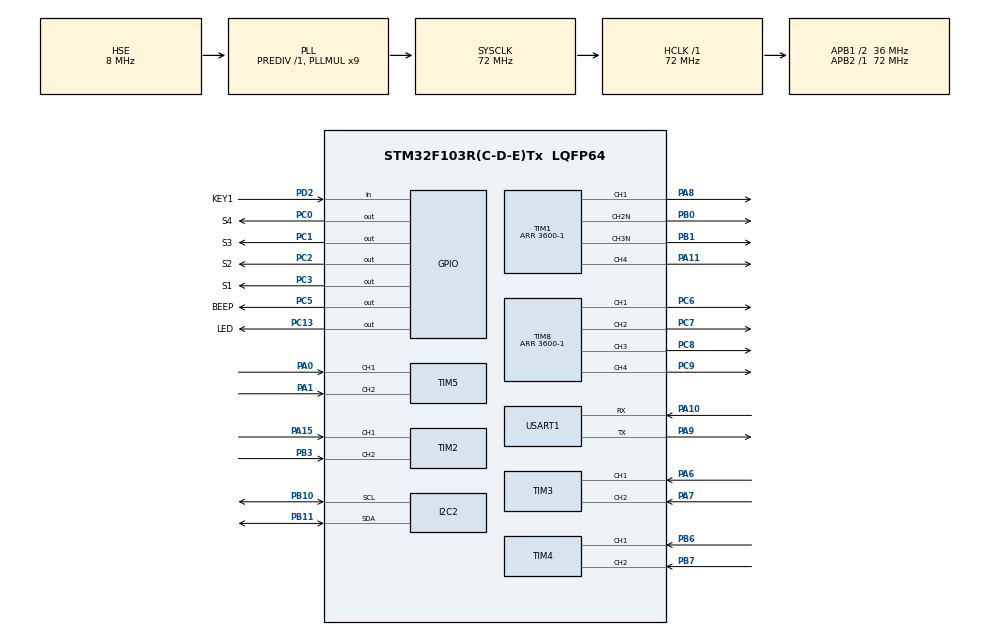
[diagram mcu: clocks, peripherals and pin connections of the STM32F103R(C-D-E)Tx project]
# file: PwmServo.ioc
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Dma.Request0=USART1_TX
Dma.Request1=USART1_RX
Dma.USART1_RX.1.Direction=DMA_PERIPH_TO_MEMORY
Dma.USART1_RX.1.Instance=DMA1_Channel5
Dma.USART1_RX.1.MemDataAlignment=DMA_MDATAALIGN_BYTE
Dma.USART1_RX.1.MemInc=DMA_MINC_ENABLE
Dma.USART1_RX.1.Mode=DMA_NORMAL
Dma.USART1_RX.1.PeriphDataAlignment=DMA_PDATAALIGN_BYTE
Dma.USART1_RX.1.PeriphInc=DMA_PINC_DISABLE
Dma.USART1_RX.1.Priority=DMA_PRIORITY_LOW
Dma.USART1_TX.0.Direction=DMA_MEMORY_TO_PERIPH
Dma.USART1_TX.0.Instance=DMA1_Channel4
Dma.USART1_TX.0.MemDataAlignment=DMA_MDATAALIGN_BYTE
Dma.USART1_TX.0.MemInc=DMA_MINC_ENABLE
Dma.USART1_TX.0.Mode=DMA_NORMAL
Dma.USART1_TX.0.PeriphDataAlignment=DMA_PDATAALIGN_BYTE
Dma.USART1_TX.0.PeriphInc=DMA_PINC_DISABLE
Dma.USART1_TX.0.Priority=DMA_PRIORITY_LOW
I2C2.I2C_Mode=I2C_Fast
I2C2.OwnAddress=0x12
Mcu.Family=STM32F1
Mcu.Name=STM32F103R(C-D-E)Tx
Mcu.Package=LQFP64
NVIC.DMA1_Channel4_IRQn=true\:0\:0\:false\:false\:true\:false\:true\:true
NVIC.DMA1_Channel5_IRQn=true\:0\:0\:false\:false\:true\:false\:true\:true
NVIC.I2C2_ER_IRQn=true\:0\:0\:false\:false\:true\:true\:true\:true
NVIC.I2C2_EV_IRQn=true\:0\:0\:false\:false\:true\:true\:true\:true
NVIC.PriorityGroup=NVIC_PRIORITYGROUP_4
NVIC.TIM7_IRQn=true\:0\:0\:false\:false\:true\:true\:true\:true
NVIC.USART1_IRQn=true\:0\:0\:false\:false\:true\:true\:true\:true
PA0-WKUP.Signal=S_TIM5_CH1
PA1.Signal=S_TIM5_CH2
PA10.Mode=Asynchronous
PA10.Signal=USART1_RX
PA11.Signal=S_TIM1_CH4
PA13.Mode=Serial_Wire
PA13.Signal=SYS_JTMS-SWDIO
PA14.Mode=Serial_Wire
PA14.Signal=SYS_JTCK-SWCLK
PA15.Signal=S_TIM2_CH1_ETR
PA6.Signal=S_TIM3_CH1
PA7.Signal=S_TIM3_CH2
PA8.Signal=S_TIM1_CH1
PA9.Mode=Asynchronous
PA9.Signal=USART1_TX
PB0.Mode=PWM Generation2 CH2N
PB0.Signal=TIM1_CH2N
PB1.Mode=PWM Generation3 CH3N
PB1.Signal=TIM1_CH3N
PB10.Mode=I2C
PB10.Signal=I2C2_SCL
PB11.Mode=I2C
PB11.Signal=I2C2_SDA
PB3.Signal=S_TIM2_CH2
PB6.Signal=S_TIM4_CH1
PB7.Signal=S_TIM4_CH2
PC0.GPIO_Label=S4
PC0.GPIO_Speed=GPIO_SPEED_FREQ_HIGH
PC0.Signal=GPIO_Output
PC1.GPIO_Label=S3
PC1.GPIO_Speed=GPIO_SPEED_FREQ_HIGH
PC1.Signal=GPIO_Output
PC13-TAMPER-RTC.GPIO_Label=LED
PC13-TAMPER-RTC.Signal=GPIO_Output
PC2.GPIO_Label=S2
PC2.GPIO_Speed=GPIO_SPEED_FREQ_HIGH
PC2.Signal=GPIO_Output
PC3.GPIO_Label=S1
PC3.GPIO_Speed=GPIO_SPEED_FREQ_HIGH
PC3.Signal=GPIO_Output
PC5.GPIO_Label=BEEP
PC5.Signal=GPIO_Output
PC6.Signal=S_TIM8_CH1
PC7.Signal=S_TIM8_CH2
PC8.Signal=S_TIM8_CH3
PC9.Signal=S_TIM8_CH4
PD0-OSC_IN.Mode=HSE-External-Oscillator
PD0-OSC_IN.Signal=RCC_OSC_IN
PD1-OSC_OUT.Mode=HSE-External-Oscillator
PD1-OSC_OUT.Signal=RCC_OSC_OUT
PD2.GPIO_Label=KEY1
PD2.GPIO_PuPd=GPIO_PULLUP
PD2.Signal=GPIO_Input
ProjectManager.HeapSize=0x200
ProjectManager.StackSize=0x400
ProjectManager.TargetToolchain=STM32CubeIDE
RCC.AHBFreq_Value=72000000
RCC.APB1CLKDivider=RCC_HCLK_DIV2
RCC.APB1Freq_Value=36000000
RCC.APB1TimFreq_Value=72000000
RCC.APB2Freq_Value=72000000
RCC.APB2TimFreq_Value=72000000
RCC.HCLKFreq_Value=72000000
RCC.PLLMUL=RCC_PLL_MUL9
RCC.PLLSourceVirtual=RCC_PLLSOURCE_HSE
RCC.SYSCLKFreq_VALUE=72000000
RCC.SYSCLKSource=RCC_SYSCLKSOURCE_PLLCLK
RCC.USBFreq_Value=72000000
SH.S_TIM1_CH1.0=TIM1_CH1,PWM Generation1 CH1
SH.S_TIM1_CH4.0=TIM1_CH4,PWM Generation4 CH4
SH.S_TIM2_CH1_ETR.0=TIM2_CH1,Encoder_Interface
SH.S_TIM2_CH2.0=TIM2_CH2,Encoder_Interface
SH.S_TIM3_CH1.0=TIM3_CH1,Encoder_Interface
SH.S_TIM3_CH2.0=TIM3_CH2,Encoder_Interface
SH.S_TIM4_CH1.0=TIM4_CH1,Encoder_Interface
SH.S_TIM4_CH2.0=TIM4_CH2,Encoder_Interface
SH.S_TIM5_CH1.0=TIM5_CH1,Encoder_Interface
SH.S_TIM5_CH2.0=TIM5_CH2,Encoder_Interface
SH.S_TIM8_CH1.0=TIM8_CH1,PWM Generation1 CH1
SH.S_TIM8_CH2.0=TIM8_CH2,PWM Generation2 CH2
SH.S_TIM8_CH3.0=TIM8_CH3,PWM Generation3 CH3
SH.S_TIM8_CH4.0=TIM8_CH4,PWM Generation4 CH4
TIM1.AutoReloadPreload=TIM_AUTORELOAD_PRELOAD_ENABLE
TIM1.Channel-PWM\ Generation1\ CH1=TIM_CHANNEL_1
TIM1.Channel-PWM\ Generation2\ CH2N=TIM_CHANNEL_2
TIM1.Channel-PWM\ Generation3\ CH3N=TIM_CHANNEL_3
TIM1.Channel-PWM\ Generation4\ CH4=TIM_CHANNEL_4
TIM1.Period=3600-1
TIM2.EncoderMode=TIM_ENCODERMODE_TI12
TIM3.EncoderMode=TIM_ENCODERMODE_TI12
TIM4.EncoderMode=TIM_ENCODERMODE_TI12
TIM5.EncoderMode=TIM_ENCODERMODE_TI12
TIM7.AutoReloadPreload=TIM_AUTORELOAD_PRELOAD_ENABLE
TIM7.Period=9
TIM7.Prescaler=71
TIM7.TIM_MasterOutputTrigger=TIM_TRGO_RESET
TIM8.AutoReloadPreload=TIM_AUTORELOAD_PRELOAD_ENABLE
TIM8.Channel-PWM\ Generation1\ CH1=TIM_CHANNEL_1
TIM8.Channel-PWM\ Generation2\ CH2=TIM_CHANNEL_2
TIM8.Channel-PWM\ Generation3\ CH3=TIM_CHANNEL_3
TIM8.Channel-PWM\ Generation4\ CH4=TIM_CHANNEL_4
TIM8.Period=3600-1
USART1.VirtualMode=VM_ASYNC
VP_TIM1_VS_ClockSourceINT.Mode=Internal
VP_TIM7_VS_ClockSourceINT.Mode=Enable_Timer
VP_TIM8_VS_ClockSourceINT.Mode=Internal
board=custom

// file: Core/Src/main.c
/* USER CODE BEGIN Header */
/**
  ******************************************************************************
  * @file           : main.c
  * @brief          : Main program body
  ******************************************************************************
  * @attention
  *
  * <h2><center>&copy; Copyright (c) 2022 STMicroelectronics.
  * All rights reserved.</center></h2>
  *
  * This software component is licensed by ST under BSD 3-Clause license,
  * the "License"; You may not use this file except in compliance with the
  * License. You may obtain a copy of the License at:
  *                        opensource.org/licenses/BSD-3-Clause
  *
  ******************************************************************************
  */
/* USER CODE END Header */
#include "main.h"
#include "dma.h"
#include "i2c.h"
#include "tim.h"
#include "usart.h"
#include "gpio.h"

/* USER CODE BEGIN Includes */
#include "bsp.h"

/* USER CODE END Includes */

void SystemClock_Config(void);

int main(void)
{

  /* MCU Configuration--------------------------------------------------------*/

  /* Reset of all peripherals, Initializes the Flash interface and the Systick. */
  HAL_Init();

  /* Configure the system clock */
  SystemClock_Config();

  /* Initialize all configured peripherals */
  MX_GPIO_Init();
  MX_DMA_Init();
  MX_TIM7_Init();
  MX_I2C2_Init();
  MX_TIM1_Init();
  MX_TIM8_Init();
  MX_USART1_UART_Init();
  MX_TIM2_Init();
  MX_TIM3_Init();
  MX_TIM4_Init();
  MX_TIM5_Init();
  /* USER CODE BEGIN 2 */
  Bsp_Init();

  /* USER CODE END 2 */

  /* Infinite loop */
  /* USER CODE BEGIN WHILE */
  while (1)
  {
    Bsp_Loop();

    /* USER CODE END WHILE */

  }
}

void SystemClock_Config(void)
{
  RCC_OscInitTypeDef RCC_OscInitStruct = {0};
  RCC_ClkInitTypeDef RCC_ClkInitStruct = {0};

  /** Initializes the RCC Oscillators according to the specified parameters
  * in the RCC_OscInitTypeDef structure.
  */
  RCC_OscInitStruct.OscillatorType = RCC_OSCILLATORTYPE_HSE;
  RCC_OscInitStruct.HSEState = RCC_HSE_ON;
  RCC_OscInitStruct.HSEPredivValue = RCC_HSE_PREDIV_DIV1;
  RCC_OscInitStruct.HSIState = RCC_HSI_ON;
  RCC_OscInitStruct.PLL.PLLState = RCC_PLL_ON;
  RCC_OscInitStruct.PLL.PLLSource = RCC_PLLSOURCE_HSE;
  RCC_OscInitStruct.PLL.PLLMUL = RCC_PLL_MUL9;
  if (HAL_RCC_OscConfig(&RCC_OscInitStruct) != HAL_OK)
  {
    Error_Handler();
  }

  /** Initializes the CPU, AHB and APB buses clocks
  */
  RCC_ClkInitStruct.ClockType = RCC_CLOCKTYPE_HCLK|RCC_CLOCKTYPE_SYSCLK
                              |RCC_CLOCKTYPE_PCLK1|RCC_CLOCKTYPE_PCLK2;
  RCC_ClkInitStruct.SYSCLKSource = RCC_SYSCLKSOURCE_PLLCLK;
  RCC_ClkInitStruct.AHBCLKDivider = RCC_SYSCLK_DIV1;
  RCC_ClkInitStruct.APB1CLKDivider = RCC_HCLK_DIV2;
  RCC_ClkInitStruct.APB2CLKDivider = RCC_HCLK_DIV1;

  if (HAL_RCC_ClockConfig(&RCC_ClkInitStruct, FLASH_LATENCY_2) != HAL_OK)
  {
    Error_Handler();
  }
}

void Error_Handler(void)
{
  __disable_irq();
  while (1)
  {
  }
}
